# CAPTIO_356.0 register map
Vendor: Texas Instruments
Peripheral module from a debugger description file (folder MSP432).
Registers are 16-bit, access per field, no defined reset value unless marked. A register's access mark holds for its fields unless they carry their own. Offsets are as the file gives them; lines under a group give offsets from that group; [hi:lo] are bit positions; {n}, {i} and the like mark numbered series; 'fields as' and 'values as' point back to an identical list; <NAME> marks a mode.

## CAPTIO
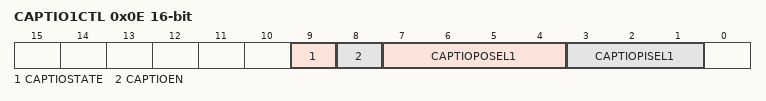
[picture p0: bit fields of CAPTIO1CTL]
0x0E CAPTIO1CTL — Capacitive Touch IO 0 Control Register
  [9] CAPTIOSTATE ro — Capacitive Touch IO state
    0=Curent state 0 or Capacitive Touch IO is disabled; 1=Current state 1
  [8] CAPTIOEN rw — Capacitive Touch IO enable
    0=OFF (All Capacitive Touch IOs are disabled. Signal towards timers is 0.); 1=ON (Selected Capacitive Touch IO is enabled)
  [7:4] CAPTIOPOSEL1 rw — Capacitive Touch IO port select
    0=PJ (Px = PJ); {v}=P{v} (Px = P{v}) (v=1..15)
  [3:1] CAPTIOPISEL1 rw — Capacitive Touch IO pin select
    0=CAPTIOPISEL_0 (Px.0); 1=CAPTIOPISEL_1 (Px.1); 2=CAPTIOPISEL_2 (Px.2); 3=CAPTIOPISEL_3 (Px.3); 4=CAPTIOPISEL_4 (Px.4); 5=CAPTIOPISEL_5 (Px.5); 6=CAPTIOPISEL_6 (Px.6); 7=CAPTIOPISEL_7 (Px.7)
